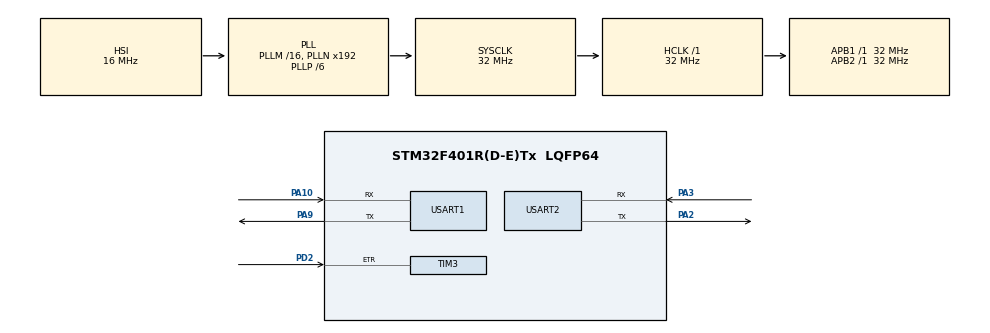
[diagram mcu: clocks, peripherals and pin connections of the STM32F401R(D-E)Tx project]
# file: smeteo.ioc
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Mcu.Family=STM32F4
Mcu.Name=STM32F401R(D-E)Tx
Mcu.Package=LQFP64
NVIC.PriorityGroup=NVIC_PRIORITYGROUP_4
NVIC.TIM3_IRQn=true\:0\:0\:false\:false\:true\:true\:true\:true
NVIC.USART1_IRQn=true\:0\:0\:false\:false\:true\:true\:true\:true
PA10.Mode=Asynchronous
PA10.Signal=USART1_RX
PA2.Mode=Asynchronous
PA2.Signal=USART2_TX
PA3.Mode=Asynchronous
PA3.Signal=USART2_RX
PA9.Mode=Asynchronous
PA9.Signal=USART1_TX
PD2.Signal=S_TIM3_ETR
PH0\ -\ OSC_IN.Mode=HSE-External-Oscillator
PH0\ -\ OSC_IN.Signal=RCC_OSC_IN
PH1\ -\ OSC_OUT.Mode=HSE-External-Oscillator
PH1\ -\ OSC_OUT.Signal=RCC_OSC_OUT
ProjectManager.HeapSize=0x200
ProjectManager.StackSize=0x400
ProjectManager.TargetToolchain=Makefile
RCC.AHBFreq_Value=32000000
RCC.APB1Freq_Value=32000000
RCC.APB1TimFreq_Value=32000000
RCC.APB2Freq_Value=32000000
RCC.APB2TimFreq_Value=32000000
RCC.CortexFreq_Value=32000000
RCC.HCLKFreq_Value=32000000
RCC.HSE_VALUE=25000000
RCC.HSI_VALUE=16000000
RCC.LSE_VALUE=32768
RCC.PLLP=RCC_PLLP_DIV6
RCC.SYSCLKFreq_VALUE=32000000
RCC.SYSCLKSource=RCC_SYSCLKSOURCE_PLLCLK
RCC.VCOOutputFreq_Value=192000000
SH.S_TIM3_ETR.0=TIM3_ETR,ClockSourceETR_Mode2
TIM3.Period=50
TIM3.Prescaler=71
USART1.VirtualMode=VM_ASYNC
USART2.VirtualMode=VM_ASYNC
VP_RTC_VS_RTC_Activate.Mode=RTC_Enabled
board=custom

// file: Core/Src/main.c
/* USER CODE BEGIN Header */
/**
  ******************************************************************************
  * @file           : main.c
  * @brief          : Main program body
  ******************************************************************************
  * @attention
  *
  * Copyright (c) 2025 STMicroelectronics.
  * All rights reserved.
  *
  * This software is licensed under terms that can be found in the LICENSE file
  * in the root directory of this software component.
  * If no LICENSE file comes with this software, it is provided AS-IS.
  *
  ******************************************************************************
  */
/* USER CODE END Header */
#include "main.h"

/* USER CODE BEGIN Includes */
#include "./modbus/port/port.h"
#include "./modbus/include/mb.h"
#include "./modbus/port/mt_port.h"
/* USER CODE END Includes

/* USER CODE BEGIN PD */
#define REG_INPUT_START 1000
#define REG_INPUT_NREGS 8

/* USER CODE END PD */

RTC_HandleTypeDef hrtc;

TIM_HandleTypeDef htim3;

UART_HandleTypeDef huart1;
UART_HandleTypeDef huart2;

/* USER CODE BEGIN PV */
// static USHORT usRegInputStart = REG_INPUT_START;
// static USHORT usRegInputBuf[REG_INPUT_NREGS] = {'M', 'o', 'd', 'b', 'u', 's', 0, 0};
/* USER CODE END PV */

void SystemClock_Config(void);
static void MX_GPIO_Init(void);
static void MX_RTC_Init(void);
static void MX_USART2_UART_Init(void);
static void MX_TIM3_Init(void);
static void MX_USART1_UART_Init(void);

int main(void)
{

  /* MCU Configuration--------------------------------------------------------*/

  /* Reset of all peripherals, Initializes the Flash interface and the Systick. */
  HAL_Init();

  /* Configure the system clock */
  SystemClock_Config();

  /* Initialize all configured peripherals */
  MX_GPIO_Init();
  MX_RTC_Init();
  MX_USART2_UART_Init();
  MX_TIM3_Init();
  MX_USART1_UART_Init();
  /* USER CODE BEGIN 2 */

  MT_PORT_SetTimerModule(&htim3);
  MT_PORT_SetUartModule(&huart1);
  // eMBErrorCode eStatus;
  // eStatus = eMBInit(MB_RTU, 0x0A, 0, 19200, MB_PAR_NONE, 1);
  // eStatus = eMBEnable();
  // if (eStatus != MB_ENOERR)
  // {
  // // Error handling
  // }

  /* USER CODE END 2 */

  /* Infinite loop */
  while (1)
  {
    // eMBPoll();
    // usRegInputBuf[REG_INPUT_NREGS - 2] =  HAL_GetTick() / 1000;
    // usRegInputBuf[REG_INPUT_NREGS - 1] =  HAL_GetTick();
  }
}

void SystemClock_Config(void)
{
  RCC_OscInitTypeDef RCC_OscInitStruct = {0};
  RCC_ClkInitTypeDef RCC_ClkInitStruct = {0};

  /** Configure the main internal regulator output voltage
  */
  __HAL_RCC_PWR_CLK_ENABLE();
  __HAL_PWR_VOLTAGESCALING_CONFIG(PWR_REGULATOR_VOLTAGE_SCALE2);

  /** Initializes the RCC Oscillators according to the specified parameters
  * in the RCC_OscInitTypeDef structure.
  */
  RCC_OscInitStruct.OscillatorType = RCC_OSCILLATORTYPE_HSI|RCC_OSCILLATORTYPE_LSI;
  RCC_OscInitStruct.HSIState = RCC_HSI_ON;
  RCC_OscInitStruct.HSICalibrationValue = RCC_HSICALIBRATION_DEFAULT;
  RCC_OscInitStruct.LSIState = RCC_LSI_ON;
  RCC_OscInitStruct.PLL.PLLState = RCC_PLL_ON;
  RCC_OscInitStruct.PLL.PLLSource = RCC_PLLSOURCE_HSI;
  RCC_OscInitStruct.PLL.PLLM = 16;
  RCC_OscInitStruct.PLL.PLLN = 192;
  RCC_OscInitStruct.PLL.PLLP = RCC_PLLP_DIV6;
  RCC_OscInitStruct.PLL.PLLQ = 4;
  if (HAL_RCC_OscConfig(&RCC_OscInitStruct) != HAL_OK)
  {
    Error_Handler();
  }

  /** Initializes the CPU, AHB and APB buses clocks
  */
  RCC_ClkInitStruct.ClockType = RCC_CLOCKTYPE_HCLK|RCC_CLOCKTYPE_SYSCLK
                              |RCC_CLOCKTYPE_PCLK1|RCC_CLOCKTYPE_PCLK2;
  RCC_ClkInitStruct.SYSCLKSource = RCC_SYSCLKSOURCE_PLLCLK;
  RCC_ClkInitStruct.AHBCLKDivider = RCC_SYSCLK_DIV1;
  RCC_ClkInitStruct.APB1CLKDivider = RCC_HCLK_DIV1;
  RCC_ClkInitStruct.APB2CLKDivider = RCC_HCLK_DIV1;

  if (HAL_RCC_ClockConfig(&RCC_ClkInitStruct, FLASH_LATENCY_1) != HAL_OK)
  {
    Error_Handler();
  }
}

static void MX_RTC_Init(void)
{

  /** Initialize RTC Only
  */
  hrtc.Instance = RTC;
  hrtc.Init.HourFormat = RTC_HOURFORMAT_24;
  hrtc.Init.AsynchPrediv = 127;
  hrtc.Init.SynchPrediv = 255;
  hrtc.Init.OutPut = RTC_OUTPUT_DISABLE;
  hrtc.Init.OutPutPolarity = RTC_OUTPUT_POLARITY_HIGH;
  hrtc.Init.OutPutType = RTC_OUTPUT_TYPE_OPENDRAIN;
  if (HAL_RTC_Init(&hrtc) != HAL_OK)
  {
    Error_Handler();
  }

}

static void MX_TIM3_Init(void)
{

  TIM_ClockConfigTypeDef sClockSourceConfig = {0};
  TIM_MasterConfigTypeDef sMasterConfig = {0};

  htim3.Instance = TIM3;
  htim3.Init.Prescaler = 71;
  htim3.Init.CounterMode = TIM_COUNTERMODE_UP;
  htim3.Init.Period = 50;
  htim3.Init.ClockDivision = TIM_CLOCKDIVISION_DIV1;
  htim3.Init.AutoReloadPreload = TIM_AUTORELOAD_PRELOAD_DISABLE;
  if (HAL_TIM_Base_Init(&htim3) != HAL_OK)
  {
    Error_Handler();
  }
  sClockSourceConfig.ClockSource = TIM_CLOCKSOURCE_ETRMODE2;
  sClockSourceConfig.ClockPolarity = TIM_CLOCKPOLARITY_NONINVERTED;
  sClockSourceConfig.ClockPrescaler = TIM_CLOCKPRESCALER_DIV1;
  sClockSourceConfig.ClockFilter = 0;
  if (HAL_TIM_ConfigClockSource(&htim3, &sClockSourceConfig) != HAL_OK)
  {
    Error_Handler();
  }
  sMasterConfig.MasterOutputTrigger = TIM_TRGO_RESET;
  sMasterConfig.MasterSlaveMode = TIM_MASTERSLAVEMODE_DISABLE;
  if (HAL_TIMEx_MasterConfigSynchronization(&htim3, &sMasterConfig) != HAL_OK)
  {
    Error_Handler();
  }

}

static void MX_USART1_UART_Init(void)
{

  huart1.Instance = USART1;
  huart1.Init.BaudRate = 115200;
  huart1.Init.WordLength = UART_WORDLENGTH_8B;
  huart1.Init.StopBits = UART_STOPBITS_1;
  huart1.Init.Parity = UART_PARITY_NONE;
  huart1.Init.Mode = UART_MODE_TX_RX;
  huart1.Init.HwFlowCtl = UART_HWCONTROL_NONE;
  huart1.Init.OverSampling = UART_OVERSAMPLING_16;
  if (HAL_UART_Init(&huart1) != HAL_OK)
  {
    Error_Handler();
  }

}

static void MX_USART2_UART_Init(void)
{

  huart2.Instance = USART2;
  huart2.Init.BaudRate = 115200;
  huart2.Init.WordLength = UART_WORDLENGTH_8B;
  huart2.Init.StopBits = UART_STOPBITS_1;
  huart2.Init.Parity = UART_PARITY_NONE;
  huart2.Init.Mode = UART_MODE_TX_RX;
  huart2.Init.HwFlowCtl = UART_HWCONTROL_NONE;
  huart2.Init.OverSampling = UART_OVERSAMPLING_16;
  if (HAL_UART_Init(&huart2) != HAL_OK)
  {
    Error_Handler();
  }

}

static void MX_GPIO_Init(void)
{

  /* GPIO Ports Clock Enable */
  __HAL_RCC_GPIOH_CLK_ENABLE();
  __HAL_RCC_GPIOA_CLK_ENABLE();
  __HAL_RCC_GPIOD_CLK_ENABLE();

}

/* USER CODE BEGIN 4 */
/* USER CODE BEGIN 4 */
/*----------------------------------------------------------------------------*/
// eMBErrorCode eMBRegInputCB(UCHAR * pucRegBuffer, USHORT usAddress, USHORT usNRegs)
// {
//   eMBErrorCode eStatus = MB_ENOERR;
//   int iRegIndex;
//   if ((usAddress >= REG_INPUT_START) &&
//       (usAddress + usNRegs <= REG_INPUT_START + REG_INPUT_NREGS))
//   {
//     iRegIndex = (int)(usAddress - usRegInputStart);
//     while(usNRegs > 0)
//     {
//         *pucRegBuffer++ = (unsigned char)(usRegInputBuf[iRegIndex] >> 8);
//         *pucRegBuffer++ = (unsigned char)(usRegInputBuf[iRegIndex] & 0xFF);
//         iRegIndex++;
//         usNRegs--;
//     }
//   }
//   else
//   {
//     eStatus = MB_ENOREG;
//   }
//   return eStatus;
// }
// /*----------------------------------------------------------------------------*/
// eMBErrorCode eMBRegHoldingCB(UCHAR * pucRegBuffer, USHORT usAddress, USHORT usNRegs,
//                              eMBRegisterMode eMode)
// {
//   return MB_ENOREG;
// }
// /*----------------------------------------------------------------------------*/
// eMBErrorCode eMBRegCoilsCB(UCHAR * pucRegBuffer, USHORT usAddress, USHORT usNCoils,
//                            eMBRegisterMode eMode)
// {
//   return MB_ENOREG;
// }
// /*----------------------------------------------------------------------------*/
// eMBErrorCode eMBRegDiscreteCB(UCHAR * pucRegBuffer, USHORT usAddress, USHORT usNDiscrete)
// {
//   return MB_ENOREG;
// }
/*----------------------------------------------------------------------------*/
/* USER CODE END 4 */
/* USER CODE END 4 */

void Error_Handler(void)
{
  __disable_irq();
  while (1)
  {
  }
}
